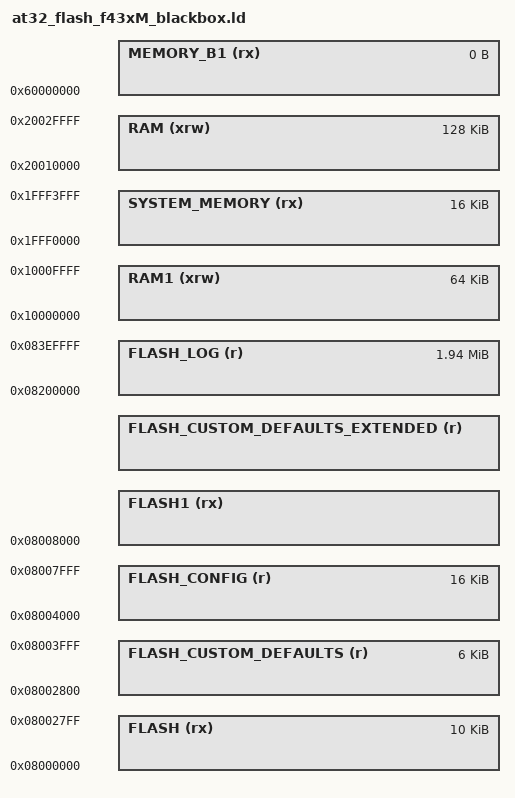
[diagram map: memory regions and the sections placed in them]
/* AT32F435xM: reserve all of bank 2 for Blackbox, including future builds. */
MEMORY
{
    FLASH (rx) : ORIGIN = 0x08000000, LENGTH = 10K
    FLASH_CUSTOM_DEFAULTS (r) : ORIGIN = 0x08002800, LENGTH = 6K
    FLASH_CONFIG (r) : ORIGIN = 0x08004000, LENGTH = 16K
    FLASH1 (rx) : ORIGIN = 0x08008000, LENGTH = DEFINED(USE_CUSTOM_DEFAULTS_EXTENDED) ? 2000K : 2016K
    FLASH_CUSTOM_DEFAULTS_EXTENDED (r) : ORIGIN = DEFINED(USE_CUSTOM_DEFAULTS_EXTENDED) ? 0x081FC000 : 0x08200000, LENGTH = DEFINED(USE_CUSTOM_DEFAULTS_EXTENDED) ? 16K : 0K
    FLASH_LOG (r) : ORIGIN = 0x08200000, LENGTH = 1984K
    SYSTEM_MEMORY (rx) : ORIGIN = 0x1FFF0000, LENGTH = 16K
    RAM1 (xrw) : ORIGIN = 0x10000000, LENGTH = 64K
    RAM (xrw) : ORIGIN = 0x20010000, LENGTH = 128K
    MEMORY_B1 (rx) : ORIGIN = 0x60000000, LENGTH = 0K
}

__flashlog_start = ORIGIN(FLASH_LOG);
__flashlog_end = ORIGIN(FLASH_LOG) + LENGTH(FLASH_LOG);
REGION_ALIAS("STACKRAM", RAM)
REGION_ALIAS("FASTRAM", RAM1)
REGION_ALIAS("VECTAB", RAM1)
REGION_ALIAS("MOVABLE_FLASH", FLASH1)
INCLUDE "at32_flash_f4_split.ld"

ASSERT(ORIGIN(FLASH1) + LENGTH(FLASH1) <= __flashlog_start, "Firmware overlaps internal Blackbox")
ASSERT(ORIGIN(FLASH_CUSTOM_DEFAULTS_EXTENDED) + LENGTH(FLASH_CUSTOM_DEFAULTS_EXTENDED) <= __flashlog_start, "Defaults overlap internal Blackbox")
